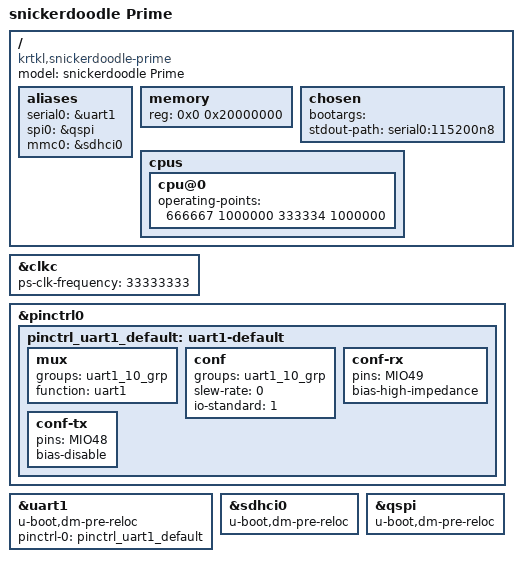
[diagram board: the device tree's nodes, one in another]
/*
 * snickerdoodle Prime Development Platform
 *
 * Copyright (c) 2016 krtkl inc.
 *
 * SPDX-License-Identifier:     GPL-2.0+
 */


/dts-v1/;
/include/ "zynq-7000.dtsi"
/ {
        model = "snickerdoodle Prime";
        compatible = "krtkl,snickerdoodle-prime", "krtkl,snickerdoodle", "xlnx,zynq-7000";

	aliases {
		serial0 = &uart1;
		spi0 = &qspi;
		mmc0 = &sdhci0;
	};

	memory {
		device_type = "memory";
		reg = <0x0 0x20000000>;
	};

	chosen {
                bootargs = "";
                stdout-path = "serial0:115200n8";
        };

	cpus {
		cpu@0 {
			operating-points = <
				/* kHz	uV */
				666667	1000000
				333334	1000000
			>;
		};
	};
};

&clkc {
	ps-clk-frequency = <33333333>;
};

&pinctrl0 {

    pinctrl_uart1_default: uart1-default {
        mux {
            groups = "uart1_10_grp";
            function = "uart1";
        };

        conf {
            groups = "uart1_10_grp";
            slew-rate = <0>;
            io-standard = <1>;
        };

        conf-rx {
            pins = "MIO49";
            bias-high-impedance;
        };

        conf-tx {
            pins = "MIO48";
            bias-disable;
        };
    };

};

&uart1 {
    u-boot,dm-pre-reloc;
    status = "okay";
    pinctrl-names = "default";
    pinctrl-0 = <&pinctrl_uart1_default>;
};

&sdhci0 {
	u-boot,dm-pre-reloc;
        status = "okay";
};

&qspi {
        u-boot,dm-pre-reloc;
        status = "okay";
};
